# RP2350 register map
Vendor: Raspberry Pi; File version: 0.1
CPU: CM33 r1p0, little endian, MPU, FPU, VTOR, 4 interrupt priority bits, 54 interrupts, 8 SAU regions
Registers are 32-bit, read-write, reset 0x0 unless marked. A register's access mark holds for its fields unless they carry their own. Offsets are from the block's base; [hi:lo] are bit positions; {n}, {i} and the like mark numbered series; 'fields as' and 'values as' point back to an identical list; <NAME> marks a mode.

## SYSINFO
Base 0x40000000
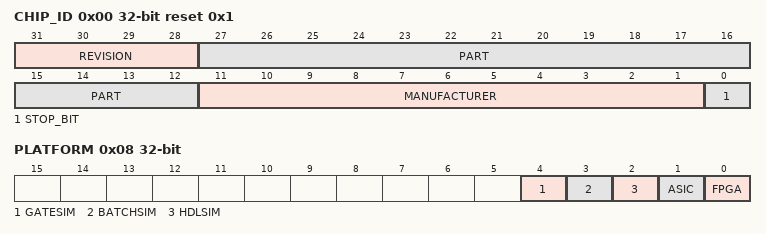
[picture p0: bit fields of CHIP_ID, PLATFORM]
0x00 CHIP_ID ro reset 0x1 — JEDEC JEP-106 compliant chip identifier.
  [31:28] REVISION, [27:12] PART, [11:1] MANUFACTURER, [0] STOP_BIT
0x04 PACKAGE_SEL ro
  [0] PACKAGE_SEL
0x08 PLATFORM ro — Platform register. Allows software to know what environment it is running in during pre-production development. Post-production, the PLATFORM is always ASIC, non-SIM.
  [4] GATESIM, [3] BATCHSIM, [2] HDLSIM, [1] ASIC, [0] FPGA
0x14 GITREF_RP2350 ro — Git hash of the chip source. Used to identify chip version.

## SYSCFG — Register block for various chip control signals
Base 0x40008000
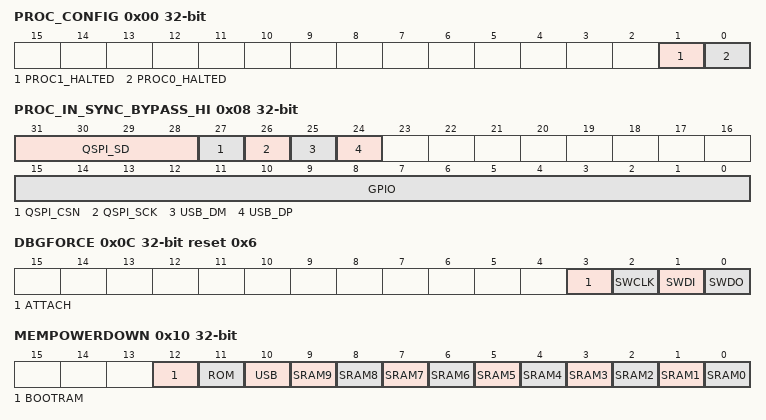
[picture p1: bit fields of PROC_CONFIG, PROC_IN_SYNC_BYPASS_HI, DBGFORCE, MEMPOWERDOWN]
0x00 PROC_CONFIG ro — Configuration for processors
  [1] PROC1_HALTED — Indication that proc1 has halted
  [0] PROC0_HALTED — Indication that proc0 has halted
0x04 PROC_IN_SYNC_BYPASS — For each bit, if 1, bypass the input synchronizer between that GPIO and the GPIO input register in the SIO. The input synchronizers should generally be unbypassed, to avoid injecting metastabilities into processors. If you're feeling brave, you can bypass to save two cycles of input latency. This register applies to GPIO 0...31.
  [31:0] GPIO
0x08 PROC_IN_SYNC_BYPASS_HI — For each bit, if 1, bypass the input synchronizer between that GPIO and the GPIO input register in the SIO. The input synchronizers should generally be unbypassed, to avoid injecting metastabilities into processors. If you're feeling brave, you can bypass to save two cycles of input latency. This register applies to GPIO 32...47. USB GPIO 56..57 QSPI GPIO 58..63
  [31:28] QSPI_SD, [27] QSPI_CSN, [26] QSPI_SCK, [25] USB_DM, [24] USB_DP, [15:0] GPIO
0x0C DBGFORCE access per field reset 0x6 — Directly control the chip SWD debug port
  [3] ATTACH rw — Attach chip debug port to syscfg controls, and disconnect it from external SWD pads.
  [2] SWCLK rw — Directly drive SWCLK, if ATTACH is set
  [1] SWDI rw — Directly drive SWDIO input, if ATTACH is set
  [0] SWDO ro — Observe the value of SWDIO output.
0x10 MEMPOWERDOWN — Control PD pins to memories. Set high to put memories to a low power state. In this state the memories will retain contents but not be accessible. Use with caution
  [12] BOOTRAM, [11] ROM, [10] USB, [n] SRAM{n} (n=0..9)
0x14 SPARE — Spare registers, Just in case.
  [7:0] SPARE

## PSM
Base 0x40018000
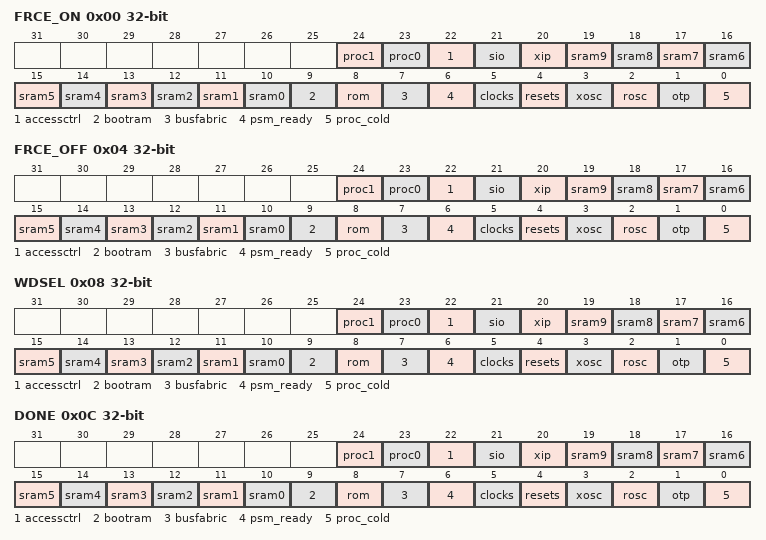
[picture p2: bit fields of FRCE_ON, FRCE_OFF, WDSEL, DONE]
0x00 FRCE_ON — Force block out of reset (i.e. power it on)
  [24] proc1, [23] proc0, [22] accessctrl, [21] sio, [20] xip, [n+10] sram{n} (n=0..9), [9] bootram, [8] rom, [7] busfabric, [6] psm_ready, [5] clocks, [4] resets, [3] xosc, [2] rosc, [1] otp, [0] proc_cold
0x04 FRCE_OFF — Force into reset (i.e. power it off)
  fields as FRCE_ON
0x08 WDSEL — Set to 1 if the watchdog should reset this
  fields as FRCE_ON
0x0C DONE ro — Is the subsystem ready?
  fields as FRCE_ON

## RESETS
Base 0x40020000
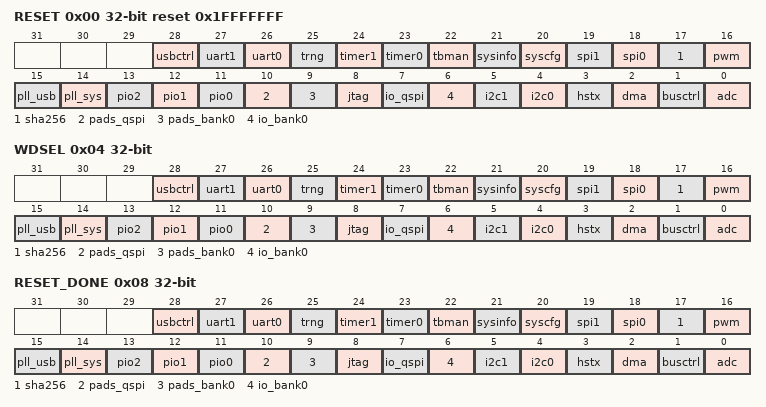
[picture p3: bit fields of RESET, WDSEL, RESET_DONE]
0x00 RESET reset 0x1FFFFFFF
  [28] usbctrl, [27] uart1, [26] uart0, [25] trng, [24] timer1, [23] timer0, [22] tbman, [21] sysinfo, [20] syscfg, [19] spi1, [18] spi0, [17] sha256, [16] pwm, [15] pll_usb, [14] pll_sys, [13] pio2, [12] pio1, [11] pio0, [10] pads_qspi, [9] pads_bank0, [8] jtag, [7] io_qspi, [6] io_bank0, [5] i2c1, [4] i2c0, [3] hstx, [2] dma, [1] busctrl, [0] adc
0x04 WDSEL
  fields as RESET
0x08 RESET_DONE ro
  fields as RESET

## PADS_BANK0
Base 0x40038000
0x00 VOLTAGE_SELECT — Voltage select. Per bank control
  [0] VOLTAGE_SELECT
    0=3v3 (Set voltage to 3.3V (DVDD >= 2V5)); 1=1v8 (Set voltage to 1.8V (DVDD <= 1V8))
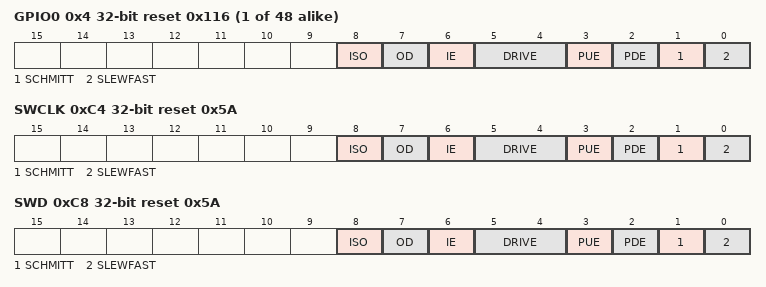
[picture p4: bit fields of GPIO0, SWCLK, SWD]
{0x4+4i} GPIO{i} reset 0x116 (i=0..47)
  [8] ISO — Pad isolation control. Remove this once the pad is configured by software.
  [7] OD — Output disable. Has priority over output enable from peripherals
  [6] IE — Input enable
  [5:4] DRIVE — Drive strength.
    0=2mA; 1=4mA; 2=8mA; 3=12mA
  [3] PUE — Pull up enable
  [2] PDE — Pull down enable
  [1] SCHMITT — Enable schmitt trigger
  [0] SLEWFAST — Slew rate control. 1 = Fast, 0 = Slow
0xC4 SWCLK reset 0x5A
  fields as GPIO0
0xC8 SWD reset 0x5A
  fields as GPIO0
